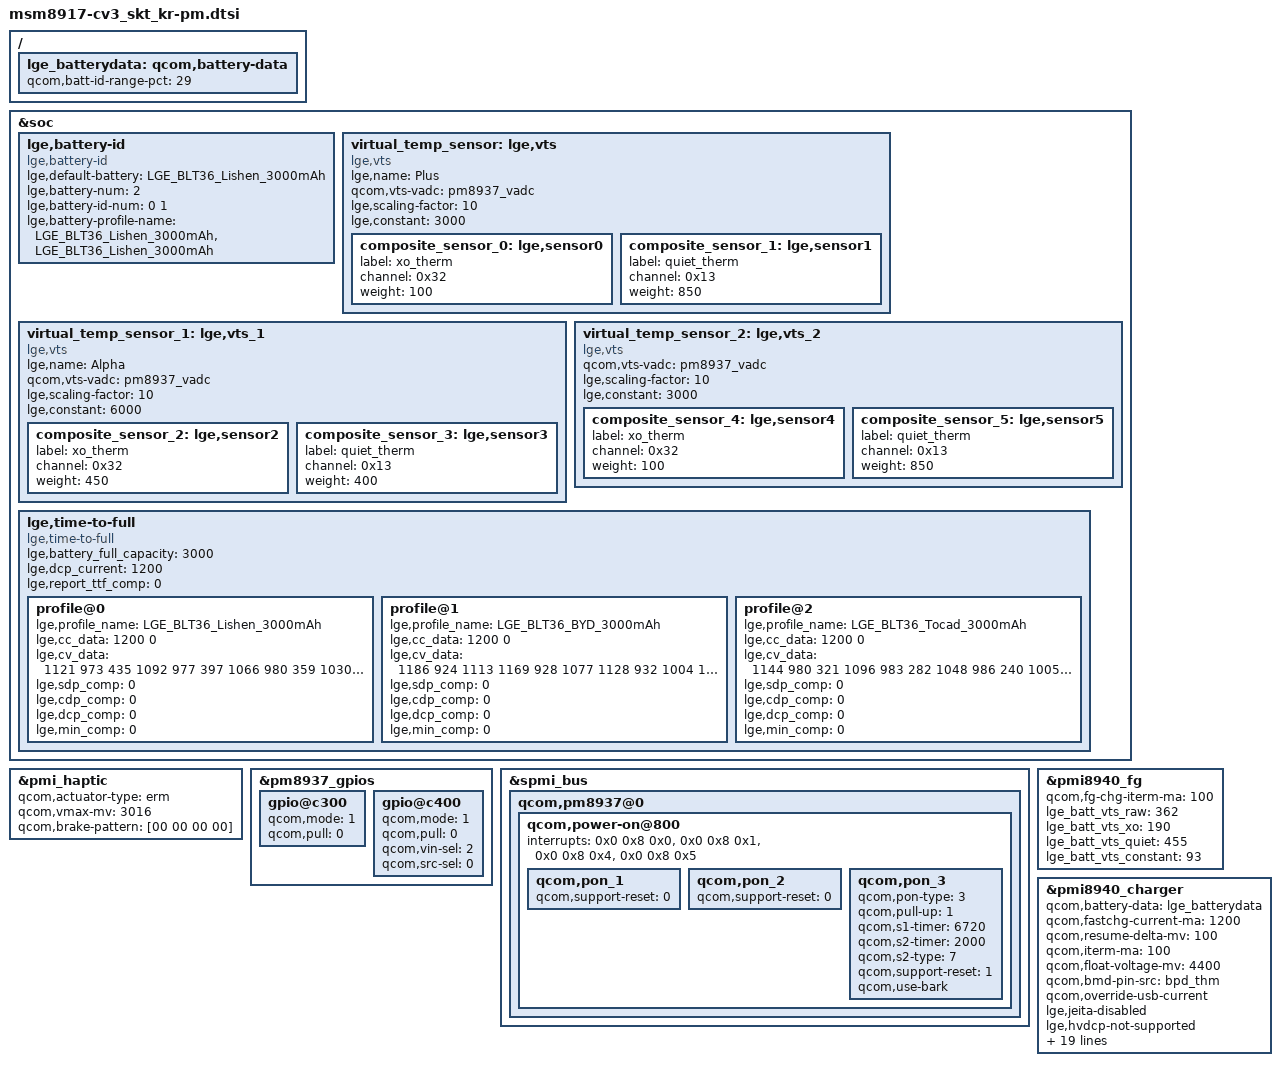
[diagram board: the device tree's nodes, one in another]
/*
 * Copyright (c) 2016, The Linux Foundation. All rights reserved.
 *
 * This program is free software; you can redistribute it and/or modify
 * it under the terms of the GNU General Public License version 2 and
 * only version 2 as published by the Free Software Foundation.
 *
 * This program is distributed in the hope that it will be useful,
 * but WITHOUT ANY WARRANTY; without even the implied warranty of
 * MERCHANTABILITY or FITNESS FOR A PARTICULAR PURPOSE.  See the
 * GNU General Public License for more details.
 */

/{
    lge_batterydata: qcom,battery-data {
		qcom,batt-id-range-pct = <29>;
		#include "../battery_profile/LGE_BLT36_Lishen_3000mAh.dtsi"
		#include "../battery_profile/LGE_BLT36_BYD_3000mAh.dtsi"
		#include "../battery_profile/LGE_BLT36_Tocad_3000mAh.dtsi"
    };
};

&soc {
	lge,battery-id{
		compatible = "lge,battery-id";
		/delete-property/ lge,restrict-mode-enabled;
		/*default battery profile*/
		lge,default-battery = "LGE_BLT36_Lishen_3000mAh";
		/*Total number of combined of battery cell and battery id */
		lge,battery-num = <2>;
		/* battery id and battery profile match numbers */
		lge,battery-id-num = <0 1>;
		/* battery profile */
		lge,battery-profile-name = "LGE_BLT36_Lishen_3000mAh",
						"LGE_BLT36_Lishen_3000mAh";
	};

	//Plus
	/* vts = (0.1*xo_therm) + (0.85*quiet_therm) + 3 */
	virtual_temp_sensor: lge,vts {
		compatible = "lge,vts";
		lge,name = "Plus";
		qcom,vts-vadc = <&pm8937_vadc>;
		lge,scaling-factor= <10>;
		lge,constant = <3000>;
		composite_sensor_0: lge,sensor0 {
			label = "xo_therm";
			channel = <0x32>;
			weight = <100>;
		};
		composite_sensor_1: lge,sensor1 {
			label = "quiet_therm";
			channel = <0x13>;
			weight = <850>;
		};
	};
	//Alpha
	/* vts = (0.45*xo_therm) + (0.4*quiet_therm) + 6 */
	virtual_temp_sensor_1: lge,vts_1 {
		compatible = "lge,vts";
		lge,name = "Alpha";
		qcom,vts-vadc = <&pm8937_vadc>;
		lge,scaling-factor= <10>;
		lge,constant = <6000>;
		composite_sensor_2: lge,sensor2 {
			label = "xo_therm";
			channel = <0x32>;
			weight = <450>;
		};
		composite_sensor_3: lge,sensor3 {
			label = "quiet_therm";
			channel = <0x13>;
			weight = <400>;
		};
	};
	//Default VTS
	/* vts = (0.1*xo_therm) + (0.85*quiet_therm) + 3 */
	virtual_temp_sensor_2: lge,vts_2 {
		compatible = "lge,vts";
		qcom,vts-vadc = <&pm8937_vadc>;
		lge,scaling-factor= <10>;
		lge,constant = <3000>;
		composite_sensor_4: lge,sensor4 {
			label = "xo_therm";
			channel = <0x32>;
			weight = <100>;
		};
		composite_sensor_5: lge,sensor5 {
			label = "quiet_therm";
			channel = <0x13>;
			weight = <850>;
		};
	};

	/* time to full */
	lge,time-to-full {
		compatible = "lge,time-to-full";
		lge,battery_full_capacity = <3000>;
		lge,dcp_current = <1200>;
		lge,report_ttf_comp = <0>;
		profile@0 {
			lge,profile_name = "LGE_BLT36_Lishen_3000mAh";
				    /* current  soc */
			lge,cc_data = < 1200	0>;
				    /* current  soc    time */
			lge,cv_data = < 1121	973	435
					1092	977	397
					1066	980	359
					1030	983	316
					986	986	270
					941	989	222
					883	992	171
					831	995	117
					788	998	60
					739	1000	0>;
			lge,sdp_comp = <0>;
			lge,cdp_comp = <0>;
			lge,dcp_comp = <0>;
			lge,min_comp = <0>;
		};
		profile@1 {
			lge,profile_name = "LGE_BLT36_BYD_3000mAh";
				    /* current  soc */
			lge,cc_data = < 1200	0>;
				    /* current  soc    time */
			lge,cv_data = < 1186	924	1113
					1169	928	1077
					1128	932	1004
					1120	937	957
					1109	941	911
					1074	945	866
					1046	949	824
					1011	954	783
					976	958	739
					942	962	695
					914	966	649
					879	970	602
					844	973	552
					814	977	501
					783	980	447
					750	983	392
					716	986	334
					688	989	274
					657	992	210
					622	995	144
					590	998	74
					563	1000	0>;
			lge,sdp_comp = <0>;
			lge,cdp_comp = <0>;
			lge,dcp_comp = <0>;
			lge,min_comp = <0>;
		};
		profile@2 {
			lge,profile_name = "LGE_BLT36_Tocad_3000mAh";
				    /* current  soc */
			lge,cc_data = < 1200	0>;
				    /* current  soc    time */
			lge,cv_data = < 1144	980	321
					1096	983	282
					1048	986	240
					1005	989	197
					959	992	151
					911	995	103
					867	998	53
					820	1000	0>;
			lge,sdp_comp = <0>;
			lge,cdp_comp = <0>;
			lge,dcp_comp = <0>;
			lge,min_comp = <0>;
		};
	};
};

&pmi_haptic{
	status = "okay";
	qcom,actuator-type = "erm";
	qcom,vmax-mv = <3016>;
	qcom,brake-pattern = [00 00 00 00];
};

&pm8937_gpios {
	gpio@c300 {
		qcom,mode = <1>;
		qcom,pull = <0>;
		status = "okay";
	};
	gpio@c400 {
		qcom,mode = <1>;
		qcom,pull = <0>;
		qcom,vin-sel = <2>;
		qcom,src-sel = <0>;
		status = "okay";
	};
};

&spmi_bus {
	qcom,pm8937@0 {
		qcom,power-on@800 {
			interrupts = <0x0 0x8 0x0>,
				     <0x0 0x8 0x1>,
				     <0x0 0x8 0x4>,
				     <0x0 0x8 0x5>;
			interrupt-names = "kpdpwr", "resin",
				"resin-bark", "kpdpwr-resin-bark";

			qcom,pon_1 {
				status = "ok";
				qcom,support-reset = <0>;
			};
			qcom,pon_2 {
				status = "ok";
				qcom,support-reset = <0>;
			};
			qcom,pon_3 {
				status = "ok";
				qcom,pon-type = <3>;
				qcom,pull-up = <1>;
				qcom,s1-timer = <6720>;
				qcom,s2-timer = <2000>;
				qcom,s2-type = <7>;
				qcom,support-reset = <1>;
				qcom,use-bark;
			};
		};
	};
};

&pmi8940_fg {
	qcom,fg-chg-iterm-ma = <100>;
	lge_batt_vts_raw = <362>;
	lge_batt_vts_xo = <190>;
	lge_batt_vts_quiet = <455>;
	lge_batt_vts_constant = <93>;
};

&pmi8940_charger {
	qcom,battery-data = <&lge_batterydata>;
	qcom,fastchg-current-ma = <1200>;
	qcom,resume-delta-mv = <100>;
	qcom,iterm-ma = <100>;
	qcom,float-voltage-mv = <4400>;
	qcom,bmd-pin-src = "bpd_thm";
	qcom,override-usb-current;
	lge,jeita-disabled;
	lge,hvdcp-not-supported;

	qcom,usb_pin-vadc = <&pmi8940_vadc>;

	/* ref resistance 200K */
	lge,no-init-cable = <0 0 0>;
	lge,cable-mhl-1k = <5000 500 500>;
	lge,cable-u-28p7k = <10000 1200 500>;
	lge,cable-28p7k = <250000 1200 500>;
	lge,cable-56k = <600000 1500 1500>;
	lge,cable-100k = <620000 1200 500>;
	lge,cable-130k = <780000 1500 1500>;
	lge,cable-180k = <870000 1200 500>;
	lge,cable-200k = <910000 1200 500>;
	lge,cable-220k = <960000 1200 500>;
	lge,cable-270k = <1050000 1200 500>;
	lge,cable-330k = <1150000 1200 500>;
	lge,cable-620k = <1380000 1200 500>;
	lge,cable-910k = <1630000 1500 1500>;
	lge,cable-none = <1900000 1200  500>;

	lge,usb-max-current-ma = <1200>;
	lge,otp-warm-ibat = <500>;
	lge,otp-cold-ibat = <500>;
};
